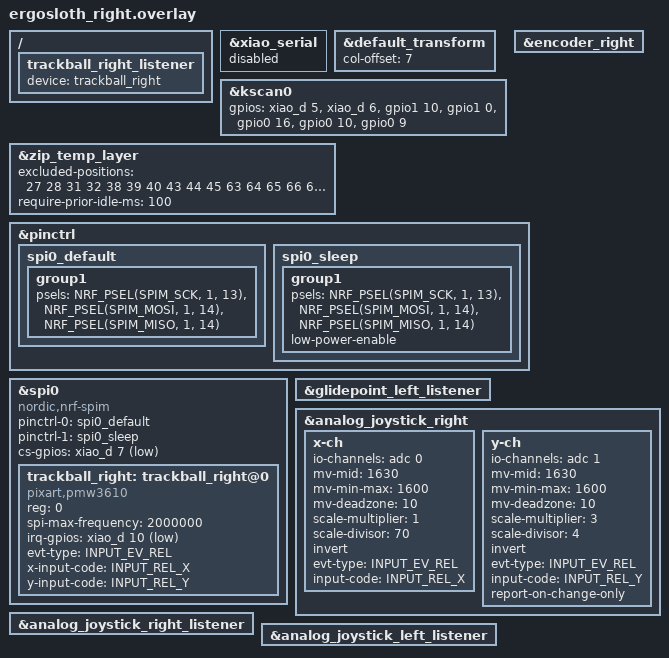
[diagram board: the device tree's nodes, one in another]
/*
 * Copyright (c) 2020 Pete Johanson
 *
 * SPDX-License-Identifier: MIT
 */

#include "ergosloth.dtsi"
#include <input/processors.dtsi>

// ZMK Studio Enable
&xiao_serial { status = "disabled"; };

&default_transform {
    col-offset = <7>;
};

&kscan0 {
    gpios
        = <&xiao_d 5 (GPIO_ACTIVE_HIGH)>
        , <&xiao_d 6 (GPIO_ACTIVE_HIGH)>
        , <&gpio1 10 (GPIO_ACTIVE_HIGH)>
        , <&gpio1  0 (GPIO_ACTIVE_HIGH)>
        , <&gpio0 16 (GPIO_ACTIVE_HIGH)>
        , <&gpio0 10 (GPIO_ACTIVE_HIGH)>
        , <&gpio0  9 (GPIO_ACTIVE_HIGH)>
        ;
};

&encoder_right {
    status = "okay";
};

/ {
    trackball_right_listener {
        status = "okay";
        device = <&trackball_right>;
    };
};

// ここに指定したキーではAMLから抜けなくなる
&zip_temp_layer {
    excluded-positions = <
        27 // L Prev
		28 // L Next
		31 // R Prev
		32 // R Next
		38 // L Middle Click
		39 // L Right Click
		40 // L Left Click
		43 // R Left Click
		44 // R Right Click
		45 // R Middle Click
		63 // L Middle Click
		64 // L Right Click
		65 // L Left Click
		66 // R Left Click
		67 // R Right Click
		68 // R Middle Click
    >;
    require-prior-idle-ms = <100>;
};

&pinctrl {
    spi0_default: spi0_default {
        group1 {
            psels = <NRF_PSEL(SPIM_SCK, 1, 13)>, // xiao D8, see posix_seeed_xiao.overlay in zmk source
            <NRF_PSEL(SPIM_MOSI, 1, 14)>, // xiao D9
            <NRF_PSEL(SPIM_MISO, 1, 14)>; // The same to MOSI (Half-duplex mode)
        };
    };

    spi0_sleep: spi0_sleep {
        group1 {
            psels = <NRF_PSEL(SPIM_SCK, 1, 13)>,
                    <NRF_PSEL(SPIM_MOSI, 1, 14)>,
                    <NRF_PSEL(SPIM_MISO, 1, 14)>;
            low-power-enable;
        };
    };
};

&spi0 {
    status = "okay";
    compatible = "nordic,nrf-spim";
    pinctrl-0 = <&spi0_default>;
    pinctrl-1 = <&spi0_sleep>;
    pinctrl-names = "default", "sleep";
    cs-gpios = <&xiao_d 7 GPIO_ACTIVE_LOW>;

    trackball_right: trackball_right@0 {
        status = "okay";
        compatible = "pixart,pmw3610";
        reg = <0>;
        // 2MHz suggested in datasheet
        spi-max-frequency = <2000000>;
        irq-gpios = <&xiao_d 10 (GPIO_ACTIVE_LOW | GPIO_PULL_UP)>;
        evt-type = <INPUT_EV_REL>;
        x-input-code = <INPUT_REL_X>;
        y-input-code = <INPUT_REL_Y>;
    };
};

&glidepoint_left_listener {
    status = "okay";
};

&analog_joystick_right {
    status = "okay";
		x-ch {
			io-channels = <&adc 0>;
			mv-mid = <1630>;
			mv-min-max = <1600>;
			mv-deadzone = <10>;
			scale-multiplier = <1>;
			scale-divisor = <70>;
			invert;
			evt-type = <INPUT_EV_REL>;
			input-code = <INPUT_REL_X>;
		};
		y-ch {
			io-channels = <&adc 1>;
			mv-mid = <1630>;
			mv-min-max = <1600>;
			mv-deadzone = <10>;
			scale-multiplier = <3>;
			scale-divisor = <4>;
			invert;
			evt-type = <INPUT_EV_REL>;
			input-code = <INPUT_REL_Y>;

			/* enable report mdoe for gamepad axix or knob */
			/* to only call input_report on quantquantized value is updated */
			/* NOTE: mouse input does NOT need this */
			report-on-change-only;

		};
};

&analog_joystick_right_listener {
	status = "okay";
};

&analog_joystick_left_listener {
	status = "okay";
};
